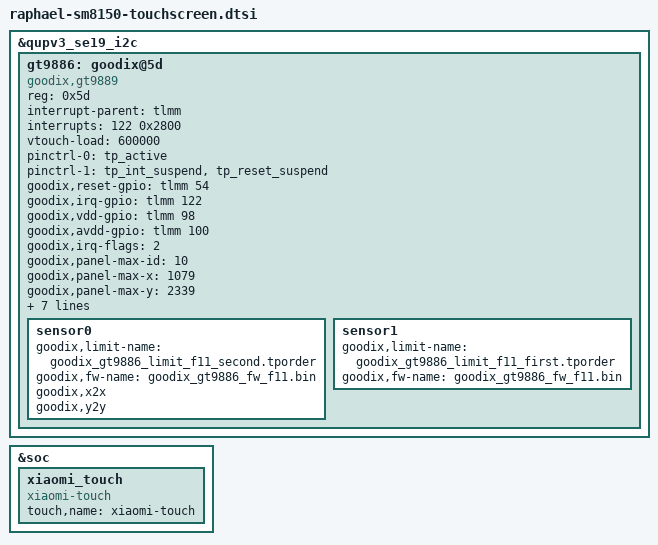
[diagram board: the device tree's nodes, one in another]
/* Copyright (c) 2020, The Linux Foundation. All rights reserved.
 *
 * This program is free software; you can redistribute it and/or modify
 * it under the terms of the GNU General Public License version 2 and
 * only version 2 as published by the Free Software Foundation.
 *
 * This program is distributed in the hope that it will be useful,
 * but WITHOUT ANY WARRANTY; without even the implied warranty of
 * MERCHANTABILITY or FITNESS FOR A PARTICULAR PURPOSE.  See the
 * GNU General Public License for more details.
 */

&qupv3_se19_i2c {
	status = "ok";
	gt9886: goodix@5d {
		compatible = "goodix,gt9889";
		reg = <0x5d>;
		status = "ok";
		interrupt-parent = <&tlmm>;
		interrupts = <122 0x2800>;
		vtouch-load = <600000>;
		pinctrl-names = "pmx_ts_active","pmx_ts_suspend";
		pinctrl-0 = <&tp_active>;
		pinctrl-1 = <&tp_int_suspend &tp_reset_suspend>;
		goodix,reset-gpio = <&tlmm 54 0x0>;
		goodix,irq-gpio = <&tlmm 122 0x2800>;
		goodix,vdd-gpio = <&tlmm 98 0x0>;			/* 3v3 */
		goodix,avdd-gpio = <&tlmm 100 0x0>;			/* 1v8 */
		goodix,irq-flags = <2>; /* 1:trigger rising, 2:trigger falling;*/
		goodix,panel-max-id = <10>;
		goodix,panel-max-x = <1079>;
		goodix,panel-max-y = <2339>;
		goodix,panel-max-w = <127>;
		goodix,panel-max-p = <127>;
		goodix,panel-max-fod = <127>;
		goodix,power-on-delay-us = <300000>; /*300ms*/
		goodix,power-off-delay-us = <5000>;
		goodix,cfg-name = "goodix_gt9886_cfg_f11.bin";
		normal-cfg = [
				];
		sensor0 {
				goodix,limit-name = "goodix_gt9886_limit_f11_second.tporder";
				goodix,fw-name = "goodix_gt9886_fw_f11.bin";
				goodix,x2x;
				goodix,y2y;
		};
		sensor1 {
				goodix,limit-name = "goodix_gt9886_limit_f11_first.tporder";
				goodix,fw-name = "goodix_gt9886_fw_f11.bin";
		};
	};
};

&soc {
    xiaomi_touch {
        compatible = "xiaomi-touch";
        status = "ok";
        touch,name = "xiaomi-touch";
    };
};
